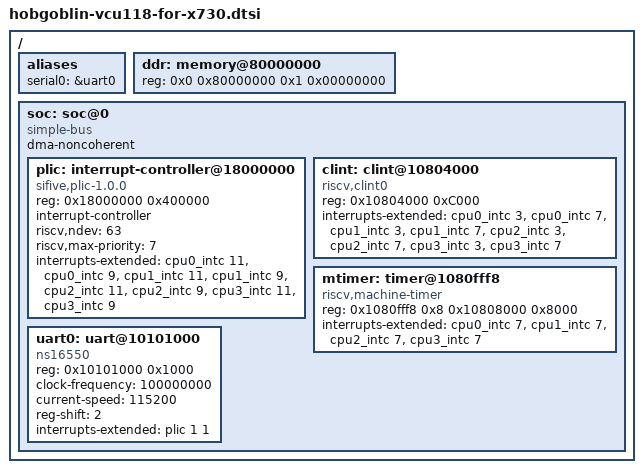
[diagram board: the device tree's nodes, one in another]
/* SPDX-License-Identifier: Apache-2.0 */
/* Added for CHERI 2026 by University of Birmingham */

/* soc and board */

/ {
	#address-cells = <2>;
	#size-cells = <2>;

	aliases {
		serial0 = &uart0;
	};

	ddr: memory@80000000 {
	device_type = "memory";
	reg = <0x0 0x80000000 0x1 0x00000000>;
	};

	soc: soc@0 {
		#address-cells = <1>;
		#size-cells = <1>;
		compatible = "simple-bus";
		ranges = <0x0 0x0 0x0 0x80000000>;
		dma-noncoherent;

		plic: interrupt-controller@18000000 {
			compatible = "sifive,plic-1.0.0";
			reg = <0x18000000 0x400000>;
			#address-cells = <0>;

			interrupt-controller;
			#interrupt-cells = <2>; /* needs to be 2 for sifive compatibility */
			riscv,ndev = <63>;
			riscv,max-priority=<7>; /* maximum interrupt priority set for Zephyr*/
			interrupts-extended = < &cpu0_intc 11 &cpu0_intc 9
						&cpu1_intc 11 &cpu1_intc 9
						&cpu2_intc 11 &cpu2_intc 9
						&cpu3_intc 11 &cpu3_intc 9
					      >;
		};

		clint: clint@10804000 {
			compatible = "riscv,clint0", "sifive,clint0";
			reg = <0x10804000 0xC000>;
			interrupts-extended = < &cpu0_intc 3 &cpu0_intc 7
						&cpu1_intc 3 &cpu1_intc 7
						&cpu2_intc 3 &cpu2_intc 7
						&cpu3_intc 3 &cpu3_intc 7
					      >;
		};

		/* v4.1 of zephyr requires mtimer node to be present in dtsi file with clint */

		mtimer: timer@1080fff8 {
			compatible = "riscv,machine-timer";
			reg = <0x1080fff8 0x8 0x10808000 0x8000>;
			reg-names = "mtime", "mtimecmp";
			interrupts-extended = <	&cpu0_intc 7
						&cpu1_intc 7
						&cpu2_intc 7
						&cpu3_intc 7
					      >;
		};

		uart0: uart@10101000 {
			/* ns16550a - zephyr notation uses ns16550 */
			compatible = "ns16550";
			reg = <0x10101000 0x1000>;
			clock-frequency = <100000000>;
			current-speed = <115200>;
			/* zephyr docs: num of interrupt cells should be set to 2: irq, priority */
			reg-shift = <2>;
			/* include the priority */
			interrupts-extended = <&plic 1 1>;
		};
	};
};
